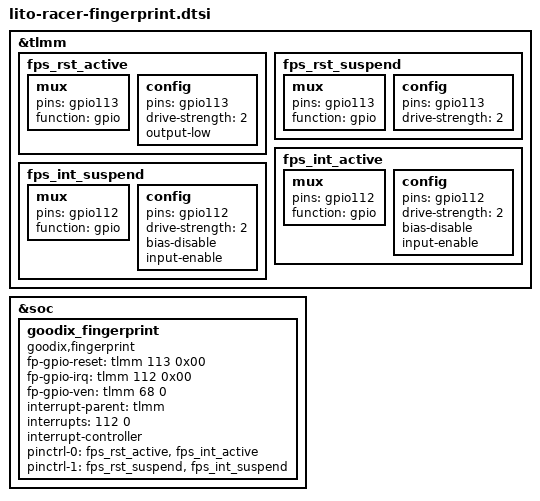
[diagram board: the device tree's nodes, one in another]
&tlmm {
	fps_rst_active: fps_rst_active {
		/* active state */
		mux {
			pins = "gpio113";
			function = "gpio";
		};

		config {
			pins = "gpio113";
			drive-strength = <2>; /* 2 MA */
			output-low;
		};
	};

	fps_rst_suspend: fps_rst_suspend {
		/* sleep state */
		mux {
			pins = "gpio113";
			function = "gpio";
		};

		config {
			pins = "gpio113";
			drive-strength = <2>; /* 2 MA */
		};
	};

	fps_int_active: fps_int_active {
		/* active state */
		mux {
			pins = "gpio112";
			function = "gpio";
		};

		config {
			pins = "gpio112";
			drive-strength = <2>; /* 2 MA */
			bias-disable;
			input-enable;
		};
	};

	fps_int_suspend: fps_int_suspend {
		/* sleep state */
		mux {
			pins = "gpio112";
			function = "gpio";
		};

		config {
			pins = "gpio112";
			drive-strength = <2>; /* 2 MA */
			bias-disable;
			input-enable;
		};
	};
};

&soc {
	goodix_fingerprint{
		compatible = "goodix,fingerprint";
		fp-gpio-reset = <&tlmm 113 0x00>;
		fp-gpio-irq = <&tlmm 112 0x00>;
		fp-gpio-ven = <&tlmm 68 0>;
		interrupt-parent = <&tlmm>;
		interrupts = <112 0>;
		interrupt-controller;
		pinctrl-names = "default", "suspend";
		pinctrl-0 = <&fps_rst_active &fps_int_active>;
		pinctrl-1 = <&fps_rst_suspend &fps_int_suspend>;
	};
};
